# XMC4300 register map
Vendor: Infineon; File version: 0.5.1 (Superset device XMC4800)
CPU: CM4 r2p0, little endian, MPU, FPU, 6 interrupt priority bits
Registers are 32-bit, read-write, reset 0x0 unless marked. A register's access mark holds for its fields unless they carry their own. Offsets are from the block's base; [hi:lo] are bit positions; {n}, {i} and the like mark numbered series; 'fields as' and 'values as' point back to an identical list.

## USB0_EP0 — Universal Serial Bus
Base 0x50040900
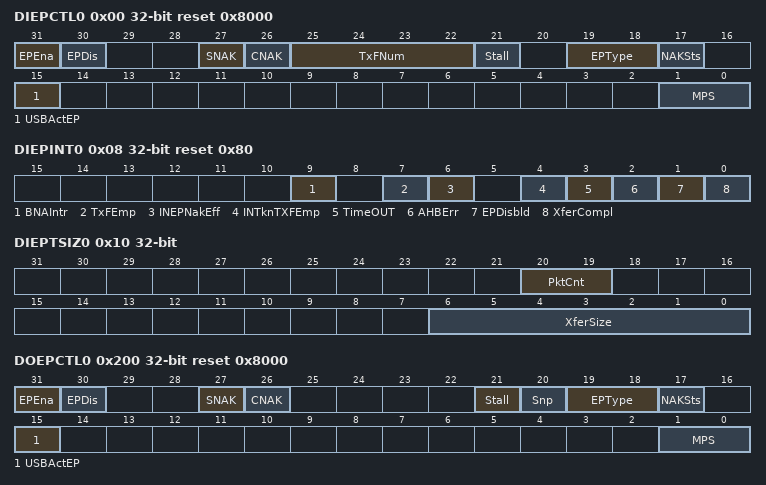
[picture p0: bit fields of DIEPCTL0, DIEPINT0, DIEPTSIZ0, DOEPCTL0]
0x00 DIEPCTL0 access per field reset 0x8000 — Device Control IN Endpoint Control Register
  [31] EPEna rw — Endpoint Enable
  [30] EPDis rw — Endpoint Disable
  [27] SNAK wo — Set NAK
  [26] CNAK wo — Clear NAK
  [25:22] TxFNum rw — TxFIFO Number
  [21] Stall rw — STALL Handshake
  [19:18] EPType ro — Endpoint Type
  [17] NAKSts ro — NAK Status
    0=The core is transmitting non-NAK handshakes based on the FIFO status; 1=The core is transmitting NAK handshakes on this endpoint
  [15] USBActEP ro — USB Active Endpoint
  [1:0] MPS rw — Maximum Packet Size
    0=64 bytes; 1=32 bytes; 2=16 bytes; 3=8 bytes
0x08 DIEPINT0 access per field reset 0x80 — Device Endpoint Interrupt Register
  [9] BNAIntr rw — BNA (Buffer Not Available) Interrupt
  [7] TxFEmp ro — Transmit FIFO Empty
  [6] INEPNakEff rw — IN Endpoint NAK Effective
  [4] INTknTXFEmp rw — IN Token Received When TxFIFO is Empty
  [3] TimeOUT rw — Timeout Condition
  [2] AHBErr rw — AHB Error
  [1] EPDisbld rw — Endpoint Disabled Interrupt
  [0] XferCompl rw — Transfer Completed Interrupt
0x10 DIEPTSIZ0 — Device IN Endpoint Transfer Size Register
  [20:19] PktCnt — Packet Count
  [6:0] XferSize — Transfer Size
0x14 DIEPDMA0 reset not defined read-has-side-effects — Device Endpoint DMA Address Register
  [31:0] DMAAddr — DMA Address
0x18 DTXFSTS0 ro — Device IN Endpoint Transmit FIFO Status Register
  [15:0] INEPTxFSpcAvail — IN Endpoint TxFIFO Space Avail
    0=Endpoint TxFIFO is full; 1=1 word available; 2=2 words available
0x1C DIEPDMAB0 ro reset not defined — Device Endpoint DMA Buffer Address Register
  [31:0] DMABufferAddr — DMA Buffer Address
0x200 DOEPCTL0 access per field reset 0x8000 — Device Control OUT Endpoint Control Register
  [31] EPEna rw — Endpoint Enable
  [30] EPDis ro — Endpoint Disable
  [27] SNAK wo — Set NAK
  [26] CNAK wo — Clear NAK
  [21] Stall rw — STALL Handshake
  [20] Snp rw — Snoop Mode
  [19:18] EPType ro — Endpoint Type
  [17] NAKSts ro — NAK Status
    values as DIEPCTL0.NAKSts
  [15] USBActEP ro — USB Active Endpoint
  [1:0] MPS ro — Maximum Packet Size
    0=64 bytes; 1=32 bytes; 2=16 bytes; 3=8 bytes
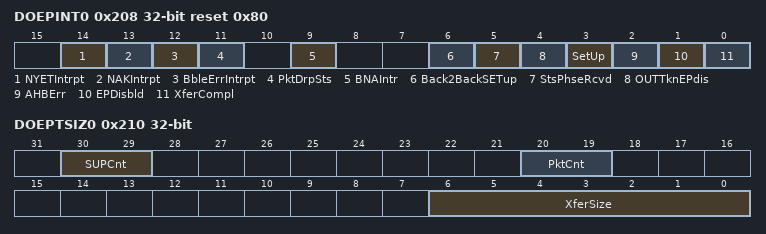
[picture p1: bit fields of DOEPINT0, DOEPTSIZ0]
0x208 DOEPINT0 reset 0x80 — Device Endpoint Interrupt Register
  [14] NYETIntrpt — NYET interrupt
  [13] NAKIntrpt — NAK interrupt
  [12] BbleErrIntrpt — BbleErr (Babble Error) interrupt
  [11] PktDrpSts — Packet Dropped Status
  [9] BNAIntr — BNA (Buffer Not Available) Interrupt
  [6] Back2BackSETup — Back-to-Back SETUP Packets Received
  [5] StsPhseRcvd — Status Phase Received For Control Write
  [4] OUTTknEPdis — OUT Token Received When Endpoint Disabled
  [3] SetUp — SETUP Phase Done
  [2] AHBErr — AHB Error
  [1] EPDisbld — Endpoint Disabled Interrupt
  [0] XferCompl — Transfer Completed Interrupt
0x210 DOEPTSIZ0 — Device OUT Endpoint Transfer Size Register
  [30:29] SUPCnt — SETUP Packet Count
    1=1 packet; 2=2 packets; 3=3 packets
  [20:19] PktCnt — Packet Count
  [6:0] XferSize — Transfer Size
0x214 DOEPDMA0 reset not defined read-has-side-effects — Device Endpoint DMA Address Register
  [31:0] DMAAddr — DMA Address
0x21C DOEPDMAB0 ro reset not defined — Device Endpoint DMA Buffer Address Register
  [31:0] DMABufferAddr — DMA Buffer Address

## USB0_CH0 — Universal Serial Bus
Base 0x50040500
Same registers: USB0_CH{n} {0x50040500+0x20*n} (n=1..13)
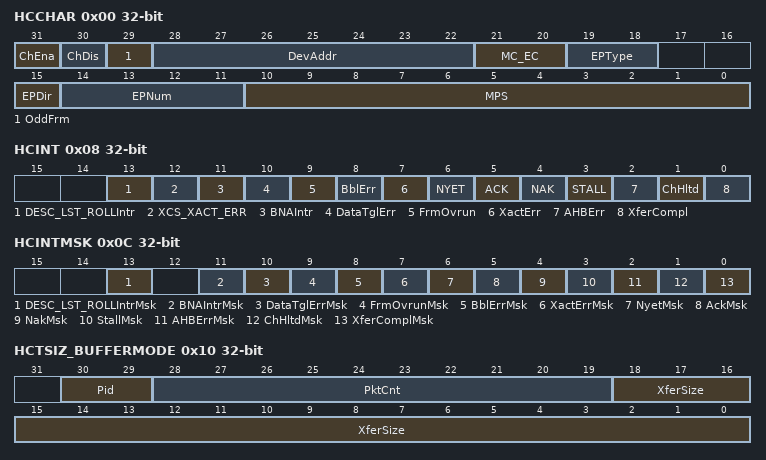
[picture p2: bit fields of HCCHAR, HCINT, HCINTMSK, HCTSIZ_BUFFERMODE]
0x00 HCCHAR — Host Channel Characteristics Register
  [31] ChEna — Channel Enable
    0=Scatter/Gather mode enabled: Indicates that the descriptor structure is not yet ready. Scatter/Gather mode disabled: Channel disabled; 1=Scatter/Gather mode enabled: Indicates that the descriptor structure and data buffer with data is setup and this channel can access the descriptor. Scatter/Gather mode disabled: Channel enabled
  [30] ChDis — Channel Disable
  [29] OddFrm — Odd Frame
    0=Even frame; 1=Odd frame
  [28:22] DevAddr — Device Address
  [21:20] MC_EC — Multi Count / Error Count
    1=1 transaction; 2=2 transactions to be issued for this endpoint per frame; 3=3 transactions to be issued for this endpoint per frame
  [19:18] EPType — Endpoint Type
    0=Control; 1=Isochronous; 2=Bulk; 3=Interrupt
  [15] EPDir — Endpoint Direction
    0=OUT; 1=IN
  [14:11] EPNum — Endpoint Number
  [10:0] MPS — Maximum Packet Size
0x08 HCINT — Host Channel Interrupt Register
  [13] DESC_LST_ROLLIntr — Descriptor rollover interrupt
  [12] XCS_XACT_ERR — Excessive Transaction Error
  [11] BNAIntr — BNA (Buffer Not Available) Interrupt
  [10] DataTglErr — Data Toggle Error
  [9] FrmOvrun — Frame Overrun
  [8] BblErr — Babble Error
  [7] XactErr — Transaction Error
  [6] NYET — NYET Response Received Interrupt
  [5] ACK — ACK Response Received/Transmitted Interrupt
  [4] NAK — NAK Response Received Interrupt
  [3] STALL — STALL Response Received Interrupt
  [2] AHBErr — AHB Error
  [1] ChHltd — Channel Halted
  [0] XferCompl — Transfer Completed
0x0C HCINTMSK — Host Channel Interrupt Mask Register
  [13] DESC_LST_ROLLIntrMsk — Descriptor rollover interrupt Mask register
  [11] BNAIntrMsk — BNA (Buffer Not Available) Interrupt mask register
  [10] DataTglErrMsk — Data Toggle Error Mask
  [9] FrmOvrunMsk — Frame Overrun Mask
  [8] BblErrMsk — Babble Error Mask
  [7] XactErrMsk — Transaction Error Mask
  [6] NyetMsk — NYET Response Received Interrupt Mask
  [5] AckMsk — ACK Response Received/Transmitted Interrupt Mask
  [4] NakMsk — NAK Response Received Interrupt Mask
  [3] StallMsk — STALL Response Received Interrupt Mask
  [2] AHBErrMsk — AHB Error Mask
  [1] ChHltdMsk — Channel Halted Mask
  [0] XferComplMsk — Transfer Completed Mask
0x10 HCTSIZ_BUFFERMODE — Host Channel Transfer Size Register [BUFFERMODE]
  [30:29] Pid
    0=DATA0; 1=DATA2; 2=DATA1; 3=MDATA (non-control)/SETUP (control)
  [28:19] PktCnt — Packet Count
  [18:0] XferSize — Transfer Size
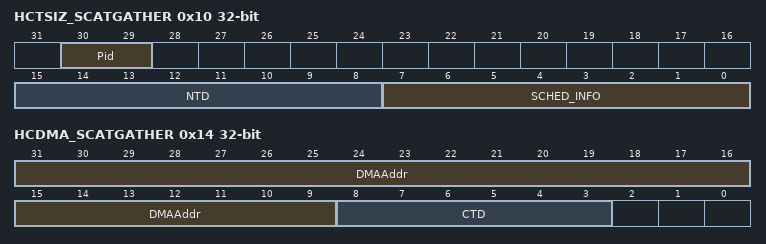
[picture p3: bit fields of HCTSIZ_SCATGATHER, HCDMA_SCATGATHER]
0x10 HCTSIZ_SCATGATHER (alternate view of HCTSIZ_BUFFERMODE) — Host Channel Transfer Size Register [SCATGATHER]
  [30:29] Pid
    0=DATA0; 1=DATA2; 2=DATA1; 3=MDATA (non-control)
  [15:8] NTD — Number of Transfer Descriptors: 0=1 descriptor, 63=64 descriptors, 1=2 descriptors, 3=4 descriptors, 7=8 descriptors, 15=16 descriptors, 31=32 descriptors, 63=64 descriptors,
  [7:0] SCHED_INFO — Schedule information
0x14 HCDMA_BUFFERMODE read-has-side-effects — Host Channel DMA Address Register [BUFFERMODE]
  [31:0] DMAAddr — DMA Address
0x14 HCDMA_SCATGATHER read-has-side-effects (alternate view of HCDMA_BUFFERMODE) — Host Channel DMA Address Register [SCATGATHER]
  [31:9] DMAAddr — DMA Address
  [8:3] CTD — Current Transfer Desc:
    0=1 descriptor; 63=64 descriptors
0x1C HCDMAB ro — Host Channel DMA Buffer Address Register
  [31:0] Buffer_Address
